# QN908X register map
Vendor: nxp.com; File version: 1.0
CPU: CM4 r0p1, little endian, MPU, FPU, VTOR, 3 interrupt priority bits
Registers are 32-bit, read-write, reset 0x0 unless marked. A register's access mark holds for its fields unless they carry their own. Offsets are from the block's base; [hi:lo] are bit positions.

## RNG
Base 0x40007C00
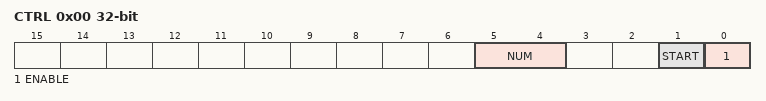
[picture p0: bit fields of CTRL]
0x00 CTRL (reset mask 0x31) — control register
  [5:4] NUM — total bits
  [1] START rw-once — write 1 to start random number generation, auto clear
  [0] ENABLE — write 1 to enable randome number generator
0x04 STAT ro — status register
  [0] BUSY — module in processing
0x08 DATA ro — random data output register
  [31:0] DATA — final random data read by SW
0x0C INT — interrupt register
  [0] DONE rw-once — random data generate done
0x10 INTEN — interrupt mask register
  [0] DONE_INTEN — random data generate done mask

## QDEC0 — qdec
Base 0x40009000
Same registers: QDEC1 0x40009800
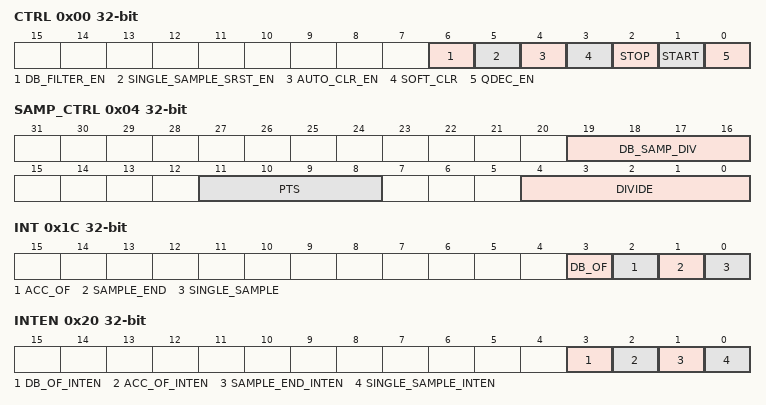
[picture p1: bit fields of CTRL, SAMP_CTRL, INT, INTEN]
0x00 CTRL (reset mask 0x71) — control register
  [6] DB_FILTER_EN, [5] SINGLE_SAMPLE_SRST_EN, [4] AUTO_CLR_EN, [3] SOFT_CLR rw-once, [2] STOP rw-once, [1] START rw-once, [0] QDEC_EN
0x04 SAMP_CTRL — QDEC sample settting register
  [19:16] DB_SAMP_DIV — Debounce filter sample clk devide cf. 8.3
  [11:8] PTS — total sample points 0~11 total 12modes cf. 8.2
    0=5 points; 1=10 points; 2=40 points; 3=80 points; 4=120 points; 5=160 points; 6=200 points; 7=240 points; 8=280 points; 9=320 points; 10=360 points; 11=400 points
  [4:0] DIVIDE — divide number to APB clk 0~20 total 21modes
0x08 SAMPLE ro — QDEC sample result register
  [1:0] SAMPLE — Sample value each time (2's complement)
0x0C ACC ro — QDEC accumulate register
  [10:0] ACC — shift counter (-1 & +1 ) normal case
0x10 ACC_R ro — QDEC accumulate snapshot register
  [10:0] ACC_R — ACC RO snapshot when END event is valid
0x14 DB ro — double sample register
  [3:0] DB — 2 trans counter ERROR case max value 15.
0x18 DB_R ro — DB snapshot register
  [3:0] DB_R — DB_R RO snapshot when END event is valid
0x1C INT — interrupt register
  [3] DB_OF rw-once — Double sample (2 trans )number is overflow
  [2] ACC_OF rw-once — Normal sample (+1/-1) number is overflow
  [1] SAMPLE_END rw-once — END event triggered
  [0] SINGLE_SAMPLE rw-once — Each time when normal sample is done
0x20 INTEN — interrupt mask register
  [3] DB_OF_INTEN — double sample overflow interrupt mask
  [2] ACC_OF_INTEN — normal sample overflow interrupt mask
  [1] SAMPLE_END_INTEN — sample end interrupt mask
  [0] SINGLE_SAMPLE_INTEN — single sample done interrupt mask
0x24 STAT ro — QDEC is running
  [0] BUSY

## CHRG
Base 0x4000A000
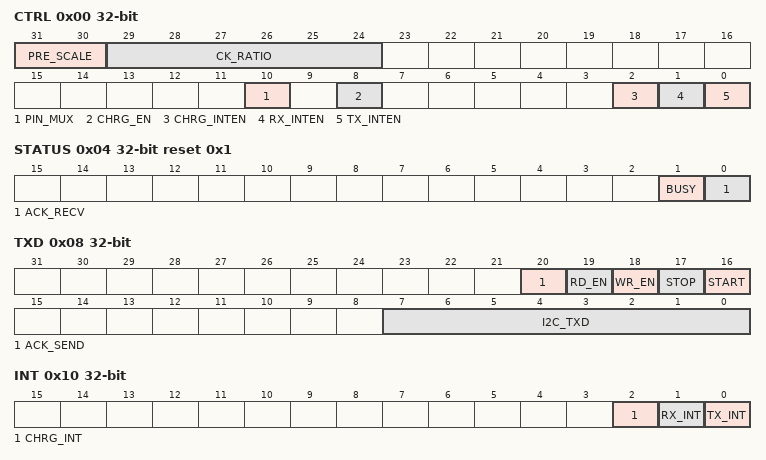
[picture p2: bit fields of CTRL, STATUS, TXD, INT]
0x00 CTRL — Charger I2C master control register
  [31:30] PRE_SCALE — I2C master clock pre scale (see section 7.1 for detail)
  [29:24] CK_RATIO — I2C master clock ratio (second stage of clock divider see section 7.1 for detail)
  [10] PIN_MUX — I2C pin mux.
  [8] CHRG_EN — Charger enable
  [2] CHRG_INTEN — charger interrupt enable
  [1] RX_INTEN — RX interrupt enable
  [0] TX_INTEN — TX interrupt enable
0x04 STATUS ro reset 0x1 — Charger I2C master status register
  [1] BUSY — I2C busy
  [0] ACK_RECV — Ack received
0x08 TXD (reset mask 0x1000FF) — Charger I2C master transmitted data control register
  [20] ACK_SEND
  [19] RD_EN rw-once — Read transfer enable this bit only generate a pulse to start the state machine
  [18] WR_EN rw-once — Write transfer enable this bit only generate a pulse to start the state machine
  [17] STOP rw-once — I2C stop this bit automatically pulls down while stop signal is finished.
  [16] START rw-once — I2C start this bit only generate a pulse to start the state machine.
  [7:0] I2C_TXD — I2C send data
0x0C RXD ro — Charger I2C master received data register
  [7:0] I2C_RXD — I2C receive data
0x10 INT — Interrupt register
  [2] CHRG_INT ro — Charger interrupt
  [1] RX_INT rw-once — RX interrupt write 1 to clear
  [0] TX_INT rw-once — TX interrupt write 1 to clear
